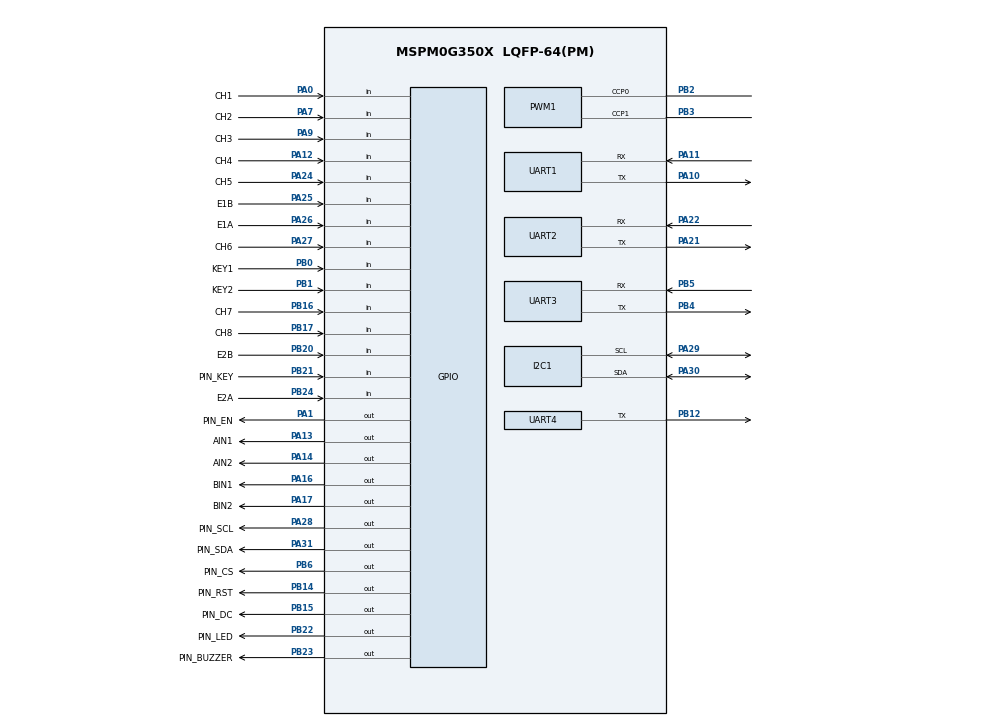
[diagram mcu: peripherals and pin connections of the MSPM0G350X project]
/**
 * 嘉立创·天猛星 MSPM0G3507 循迹小车基础外设配置。
 *
 * 本文件是 GPIO、PWM、UART、I2C 和定时器分配的唯一配置源；
 * ti_msp_dl_config.c/.h 由 SysConfig 自动生成，禁止手工修改。
 *
 * @cliArgs --device "MSPM0G350X" --package "LQFP-64(PM)" --part "Default" --product "mspm0_sdk@2.01.00.03"
 * @versions {"tool":"1.20.0+3587"}
 */

const GPIO    = scripting.addModule("/ti/driverlib/GPIO", {}, false);
const GPIO1   = GPIO.addInstance();
const GPIO2   = GPIO.addInstance();
const GPIO3   = GPIO.addInstance();
const GPIO4   = GPIO.addInstance();
const GPIO5   = GPIO.addInstance();
const GPIO6   = GPIO.addInstance();
const GPIO7   = GPIO.addInstance();
const GPIO8   = GPIO.addInstance();
const GPIO9   = GPIO.addInstance();
const GPIO10  = GPIO.addInstance();
const GPIO11  = GPIO.addInstance();
const GPIO12  = GPIO.addInstance();
const GPIO13  = GPIO.addInstance();
const GPIO14  = GPIO.addInstance();
const GPIO15  = GPIO.addInstance();
const GPIO16  = GPIO.addInstance();
const I2C     = scripting.addModule("/ti/driverlib/I2C", {}, false);
const I2C1    = I2C.addInstance();
const PWM     = scripting.addModule("/ti/driverlib/PWM", {}, false);
const PWM1    = PWM.addInstance();
const SYSCTL  = scripting.addModule("/ti/driverlib/SYSCTL");
const SYSTICK = scripting.addModule("/ti/driverlib/SYSTICK");
const TIMER   = scripting.addModule("/ti/driverlib/TIMER", {}, false);
const TIMER1  = TIMER.addInstance();
const UART    = scripting.addModule("/ti/driverlib/UART", {}, false);
const UART1   = UART.addInstance();
const UART2   = UART.addInstance();
const UART3   = UART.addInstance();
const UART4   = UART.addInstance();

/* CPU 主频配置为 80 MHz，与已跑通 Arc_Track 底盘工程保持一致。 */
const divider7       = system.clockTree["PLL_PDIV"];
divider7.divideValue = 2;

const divider9       = system.clockTree["UDIV"];
divider9.divideValue = 2;

const multiplier2         = system.clockTree["PLL_QDIV"];
multiplier2.multiplyValue = 5;

const mux8       = system.clockTree["HSCLKMUX"];
mux8.inputSelect = "HSCLKMUX_SYSPLL2X";

SYSCTL.forceDefaultClkConfig = true;
SYSCTL.clockTreeEn           = true;

SYSTICK.periodEnable  = true;
SYSTICK.systickEnable = true;
SYSTICK.period        = 16777216;

/* SSD1306 四线软件 SPI：SCL/SDA 由 GPIO 模拟，RST/DC 为控制引脚。 */
GPIO1.$name                           = "OLED_RST";
GPIO1.associatedPins[0].$name         = "PIN_RST";
GPIO1.associatedPins[0].initialValue  = "SET";
GPIO1.associatedPins[0].pin.$assign   = "PB14";

GPIO2.$name                           = "OLED_DC";
GPIO2.associatedPins[0].$name         = "PIN_DC";
GPIO2.associatedPins[0].initialValue  = "SET";
GPIO2.associatedPins[0].pin.$assign   = "PB15";

GPIO3.$name                           = "OLED_SCL";
GPIO3.associatedPins[0].$name         = "PIN_SCL";
GPIO3.associatedPins[0].initialValue  = "SET";
GPIO3.associatedPins[0].pin.$assign   = "PA28";

GPIO4.$name                           = "OLED_SDA";
GPIO4.associatedPins[0].$name         = "PIN_SDA";
GPIO4.associatedPins[0].initialValue  = "SET";
GPIO4.associatedPins[0].pin.$assign   = "PA31";

/* 天猛星板载用户按键 PB21：内部上拉，按下时为低电平。 */
GPIO5.$name                                = "USER_KEY";
GPIO5.associatedPins[0].$name              = "PIN_KEY";
GPIO5.associatedPins[0].direction          = "INPUT";
GPIO5.associatedPins[0].internalResistor   = "PULL_UP";
GPIO5.associatedPins[0].pin.$assign        = "PB21";

/* 天猛星板载 LED PB22：高电平点亮。 */
GPIO6.$name                           = "BOARD_LED";
GPIO6.associatedPins[0].$name         = "PIN_LED";
GPIO6.associatedPins[0].initialValue  = "CLEARED";
GPIO6.associatedPins[0].pin.$assign   = "PB22";

/* 板载 W25Q128 的 CS(PB6) 始终拉高；PB7~PB9 保持未分配/高阻。 */
GPIO7.$name                           = "FLASH_GUARD";
GPIO7.associatedPins[0].$name         = "PIN_CS";
GPIO7.associatedPins[0].initialValue  = "SET";
GPIO7.associatedPins[0].pin.$assign   = "PB6";

/* TB6612 左右电机方向输出；STBY 硬件固定接 3.3 V，不分配 MCU 引脚。 */
GPIO8.port                          = "PORTA";
GPIO8.$name                         = "BIN";
GPIO8.associatedPins.create(2);
GPIO8.associatedPins[0].$name       = "BIN1";
GPIO8.associatedPins[0].pin.$assign = "PA16";
GPIO8.associatedPins[1].$name       = "BIN2";
GPIO8.associatedPins[1].pin.$assign = "PA17";

GPIO9.port                          = "PORTA";
GPIO9.$name                         = "AIN";
GPIO9.associatedPins.create(2);
GPIO9.associatedPins[0].$name       = "AIN1";
GPIO9.associatedPins[0].pin.$assign = "PA13";
GPIO9.associatedPins[1].$name       = "AIN2";
GPIO9.associatedPins[1].pin.$assign = "PA14";

/* 两套正交编码器 A/B 相上升沿中断，引脚与已跑通 Arc_Track 保持一致。 */
GPIO10.$name                               = "ENCODERA";
GPIO10.associatedPins.create(2);
GPIO10.associatedPins[0].$name             = "E1A";
GPIO10.associatedPins[0].direction         = "INPUT";
GPIO10.associatedPins[0].polarity          = "RISE";
GPIO10.associatedPins[0].interruptPriority = "0";
GPIO10.associatedPins[0].interruptEn       = true;
GPIO10.associatedPins[0].pin.$assign       = "PA26";
GPIO10.associatedPins[1].$name             = "E1B";
GPIO10.associatedPins[1].direction         = "INPUT";
GPIO10.associatedPins[1].polarity          = "RISE";
GPIO10.associatedPins[1].interruptPriority = "0";
GPIO10.associatedPins[1].interruptEn       = true;
GPIO10.associatedPins[1].pin.$assign       = "PA25";

GPIO11.$name                               = "ENCODERB";
GPIO11.associatedPins.create(2);
GPIO11.associatedPins[0].$name             = "E2A";
GPIO11.associatedPins[0].direction         = "INPUT";
GPIO11.associatedPins[0].polarity          = "RISE";
GPIO11.associatedPins[0].interruptPriority = "0";
GPIO11.associatedPins[0].interruptEn       = true;
GPIO11.associatedPins[0].pin.$assign       = "PB24";
GPIO11.associatedPins[1].$name             = "E2B";
GPIO11.associatedPins[1].direction         = "INPUT";
GPIO11.associatedPins[1].polarity          = "RISE";
GPIO11.associatedPins[1].interruptPriority = "0";
GPIO11.associatedPins[1].interruptEn       = true;
GPIO11.associatedPins[1].pin.$assign       = "PB20";

/* 八路数字循迹输入：实车从左到右固定安装 CH1~CH8，均关闭内部上下拉。 */
GPIO12.port = "PORTA";
GPIO12.$name = "TRACK_A";
GPIO12.associatedPins.create(6);
GPIO12.associatedPins[0].$name = "CH1";
GPIO12.associatedPins[0].direction = "INPUT";
GPIO12.associatedPins[0].internalResistor = "NONE";
GPIO12.associatedPins[0].pin.$assign = "PA0";
GPIO12.associatedPins[1].$name = "CH2";
GPIO12.associatedPins[1].direction = "INPUT";
GPIO12.associatedPins[1].internalResistor = "NONE";
GPIO12.associatedPins[1].pin.$assign = "PA7";
GPIO12.associatedPins[2].$name = "CH3";
GPIO12.associatedPins[2].direction = "INPUT";
GPIO12.associatedPins[2].internalResistor = "NONE";
GPIO12.associatedPins[2].pin.$assign = "PA9";
GPIO12.associatedPins[3].$name = "CH4";
GPIO12.associatedPins[3].direction = "INPUT";
GPIO12.associatedPins[3].internalResistor = "NONE";
GPIO12.associatedPins[3].pin.$assign = "PA12";
GPIO12.associatedPins[4].$name = "CH5";
GPIO12.associatedPins[4].direction = "INPUT";
GPIO12.associatedPins[4].internalResistor = "NONE";
GPIO12.associatedPins[4].pin.$assign = "PA24";
GPIO12.associatedPins[5].$name = "CH6";
GPIO12.associatedPins[5].direction = "INPUT";
GPIO12.associatedPins[5].internalResistor = "NONE";
GPIO12.associatedPins[5].pin.$assign = "PA27";

GPIO13.port = "PORTB";
GPIO13.$name = "TRACK_B";
GPIO13.associatedPins.create(2);
GPIO13.associatedPins[0].$name = "CH7";
GPIO13.associatedPins[0].direction = "INPUT";
GPIO13.associatedPins[0].internalResistor = "NONE";
GPIO13.associatedPins[0].pin.$assign = "PB16";
GPIO13.associatedPins[1].$name = "CH8";
GPIO13.associatedPins[1].direction = "INPUT";
GPIO13.associatedPins[1].internalResistor = "NONE";
GPIO13.associatedPins[1].pin.$assign = "PB17";

/* 两个扩展按键均使用内部上拉，按下时为低电平。 */
GPIO14.port = "PORTB";
GPIO14.$name = "EXT_KEYS";
GPIO14.associatedPins.create(2);
GPIO14.associatedPins[0].$name = "KEY1";
GPIO14.associatedPins[0].direction = "INPUT";
GPIO14.associatedPins[0].internalResistor = "PULL_UP";
GPIO14.associatedPins[0].pin.$assign = "PB0";
GPIO14.associatedPins[1].$name = "KEY2";
GPIO14.associatedPins[1].direction = "INPUT";
GPIO14.associatedPins[1].internalResistor = "PULL_UP";
GPIO14.associatedPins[1].pin.$assign = "PB1";

/* 有源蜂鸣器控制，上电默认输出低电平关闭。 */
GPIO15.$name = "BUZZER";
GPIO15.associatedPins[0].$name = "PIN_BUZZER";
GPIO15.associatedPins[0].initialValue = "CLEARED";
GPIO15.associatedPins[0].pin.$assign = "PB23";

/* 通用使能输出，上电默认低电平关闭。 */
GPIO16.$name = "GENERAL_EN";
GPIO16.associatedPins[0].$name = "PIN_EN";
GPIO16.associatedPins[0].initialValue = "CLEARED";
GPIO16.associatedPins[0].pin.$assign = "PA1";

/* TIMA1 双通道 10 kHz 电机 PWM，周期和引脚沿用已跑通底盘。 */
PWM1.$name                      = "PWM_0";
PWM1.timerStartTimer            = true;
PWM1.pwmMode                    = "EDGE_ALIGN_UP";
PWM1.timerCount                 = 8000;
PWM1.peripheral.$assign         = "TIMA1";
PWM1.peripheral.ccp0Pin.$assign = "PB2";
PWM1.peripheral.ccp1Pin.$assign = "PB3";
PWM1.PWM_CHANNEL_0.$name        = "ti_driverlib_pwm_PWMTimerCC0";
PWM1.PWM_CHANNEL_1.$name        = "ti_driverlib_pwm_PWMTimerCC1";
PWM1.ccp0PinConfig.$name        = "ti_driverlib_gpio_PWM_C0";
PWM1.ccp1PinConfig.$name        = "ti_driverlib_gpio_PWM_C1";

/* 1 ms 系统时基；Board 层每累计 5 次调用一轮底盘闭环。 */
TIMER1.$name              = "SYSTEM_TICK";
TIMER1.timerClkPrescale   = 32;
TIMER1.timerMode          = "PERIODIC";
TIMER1.timerPeriod        = "1 ms";
TIMER1.timerStartTimer    = true;
TIMER1.interrupts         = ["ZERO"];
TIMER1.interruptPriority  = "2";
TIMER1.peripheral.$assign = "TIMG0";

/* 板载 Type-C/CH340 调试串口：UART0 115200 8N1，RX 中断进入固定环形缓冲。 */
UART1.$name                    = "DEBUG_UART";
UART1.targetBaudRate           = 115200;
UART1.enabledInterrupts        = ["RX"];
UART1.interruptPriority        = "2";
UART1.peripheral.$assign       = "UART0";
UART1.peripheral.rxPin.$assign = "PA11";
UART1.peripheral.txPin.$assign = "PA10";
UART1.txPinConfig.$name        = "ti_driverlib_gpio_DEBUG_UART_TX";
UART1.rxPinConfig.$name        = "ti_driverlib_gpio_DEBUG_UART_RX";

/* JY901S 接收串口，默认 9600 8N1，RX FIFO 中断解析 0x55 帧。 */
UART2.$name                    = "JY901S_UART";
UART2.targetBaudRate           = 9600;
UART2.enabledInterrupts        = ["RX"];
UART2.interruptPriority        = "1";
UART2.peripheral.$assign       = "UART2";
UART2.peripheral.rxPin.$assign = "PA22";
UART2.peripheral.txPin.$assign = "PA21";
UART2.txPinConfig.$name        = "ti_driverlib_gpio_JY901S_UART_TX";
UART2.rxPinConfig.$name        = "ti_driverlib_gpio_JY901S_UART_RX";

/* 可选 3.3 V DRF1609H ZigBee 透明串口，仅保留发送接口，不解析运动命令。 */
UART3.$name                    = "ZIGBEE_UART";
UART3.targetBaudRate           = 38400;
UART3.peripheral.$assign       = "UART1";
UART3.peripheral.rxPin.$assign = "PB5";
UART3.peripheral.txPin.$assign = "PB4";
UART3.txPinConfig.$name        = "ti_driverlib_gpio_ZIGBEE_UART_TX";
UART3.rxPinConfig.$name        = "ti_driverlib_gpio_ZIGBEE_UART_RX";

/* 无线 DAP 专用只发送遥测串口：UART3/PB12，115200 8N1；PB13 保持未分配。 */
UART4.$name                    = "TELEMETRY_UART";
UART4.targetBaudRate           = 115200;
UART4.direction                = "TX";
UART4.peripheral.$assign       = "UART3";
UART4.peripheral.txPin.$assign = "PB12";
UART4.txPinConfig.$name        = "ti_driverlib_gpio_TELEMETRY_UART_TX";

/* 预留 400 kHz 扩展 I2C 控制器，具体器件协议由后续 BSP 添加。 */
I2C1.$name                   = "EXPANSION_I2C";
I2C1.basicEnableController   = true;
I2C1.basicControllerBusSpeed = 400000;
I2C1.peripheral.$assign      = "I2C1";
I2C1.peripheral.sclPin.$assign = "PA29";
I2C1.peripheral.sdaPin.$assign = "PA30";

const Board = scripting.addModule("/ti/driverlib/Board", {}, false);
Board.peripheral.$suggestSolution          = "DEBUGSS";
Board.peripheral.swclkPin.$suggestSolution = "PA20";
Board.peripheral.swdioPin.$suggestSolution = "PA19";
